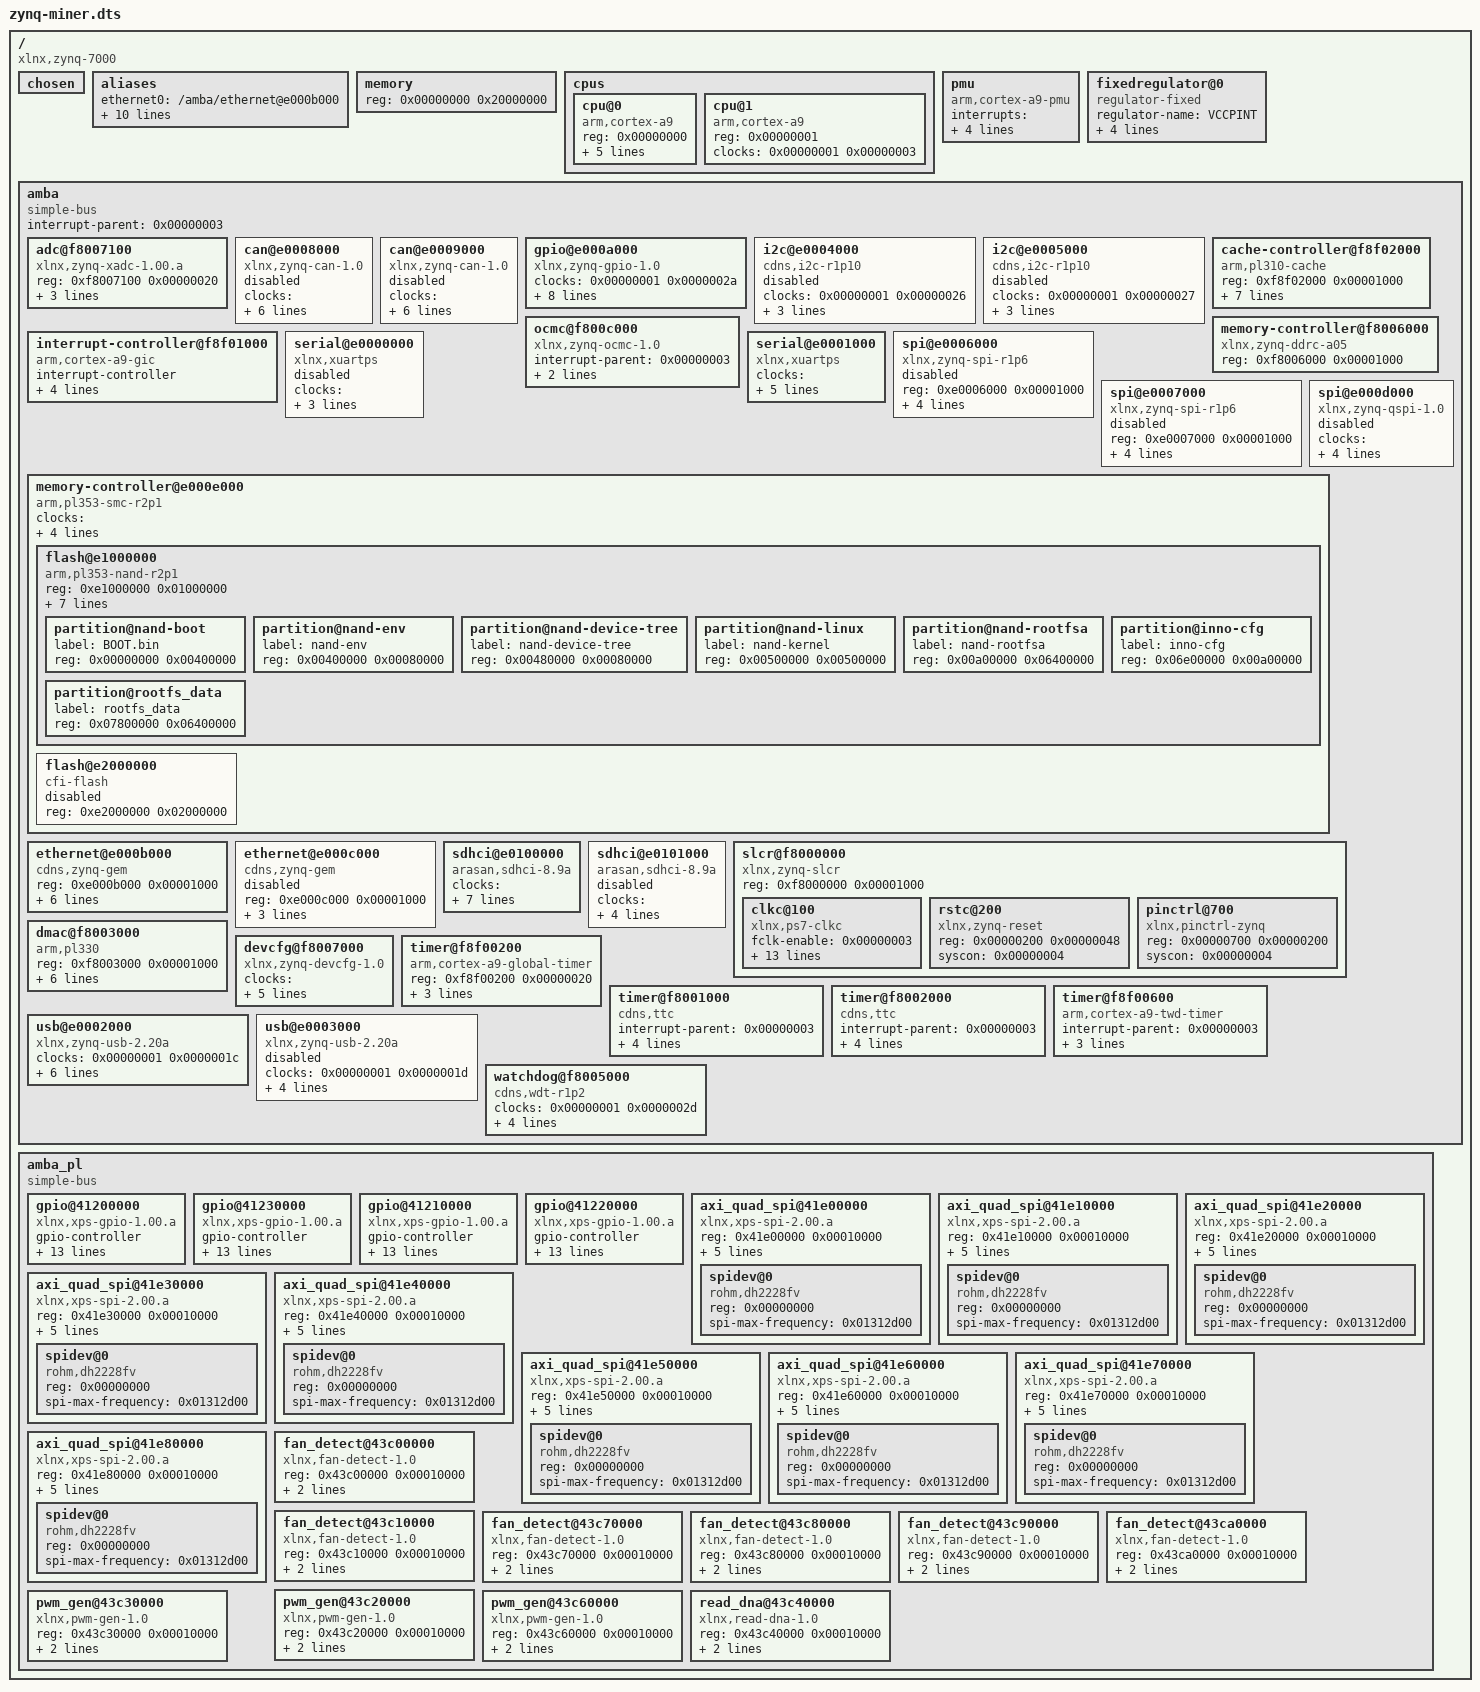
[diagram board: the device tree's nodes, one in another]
/dts-v1/;
// magic:		0xd00dfeed
// totalsize:		0x3c16 (15382)
// off_dt_struct:	0x38
// off_dt_strings:	0x36f0
// off_mem_rsvmap:	0x28
// version:		17
// last_comp_version:	16
// boot_cpuid_phys:	0x0
// size_dt_strings:	0x526
// size_dt_struct:	0x36b8

/ {
    #address-cells = <0x00000001>;
    #size-cells = <0x00000001>;
    compatible = "xlnx,zynq-7000";
    chosen {
    };
    aliases {
        ethernet0 = "/amba/ethernet@e000b000";
        serial0 = "/amba/serial@e0001000";
        spi0 = "/amba_pl/axi_quad_spi@41e00000";
        spi1 = "/amba_pl/axi_quad_spi@41e10000";
        spi2 = "/amba_pl/axi_quad_spi@41e20000";
        spi3 = "/amba_pl/axi_quad_spi@41e30000";
        spi4 = "/amba_pl/axi_quad_spi@41e40000";
        spi5 = "/amba_pl/axi_quad_spi@41e50000";
        spi6 = "/amba_pl/axi_quad_spi@41e60000";
        spi7 = "/amba_pl/axi_quad_spi@41e70000";
        spi8 = "/amba_pl/axi_quad_spi@41e80000";
    };
    memory {
        device_type = "memory";
        reg = <0x00000000 0x20000000>;
    };
    cpus {
        #address-cells = <0x00000001>;
        #size-cells = <0x00000000>;
        cpu@0 {
            compatible = "arm,cortex-a9";
            device_type = "cpu";
            reg = <0x00000000>;
            clocks = <0x00000001 0x00000003>;
            clock-latency = <0x000003e8>;
            cpu0-supply = <0x00000002>;
            operating-points = <0x000a2c2a 0x000f4240 0x00051615 0x000f4240>;
        };
        cpu@1 {
            compatible = "arm,cortex-a9";
            device_type = "cpu";
            reg = <0x00000001>;
            clocks = <0x00000001 0x00000003>;
        };
    };
    pmu {
        compatible = "arm,cortex-a9-pmu";
        interrupts = <0x00000000 0x00000005 0x00000004 0x00000000 0x00000006 0x00000004>;
        interrupt-parent = <0x00000003>;
        reg = <0xf8891000 0x00001000 0xf8893000 0x00001000>;
    };
    fixedregulator@0 {
        compatible = "regulator-fixed";
        regulator-name = "VCCPINT";
        regulator-min-microvolt = <0x000f4240>;
        regulator-max-microvolt = <0x000f4240>;
        regulator-boot-on;
        regulator-always-on;
        linux,phandle = <0x00000002>;
        phandle = <0x00000002>;
    };
    amba {
        compatible = "simple-bus";
        #address-cells = <0x00000001>;
        #size-cells = <0x00000001>;
        interrupt-parent = <0x00000003>;
        ranges;
        adc@f8007100 {
            compatible = "xlnx,zynq-xadc-1.00.a";
            reg = <0xf8007100 0x00000020>;
            interrupts = <0x00000000 0x00000007 0x00000004>;
            interrupt-parent = <0x00000003>;
            clocks = <0x00000001 0x0000000c>;
        };
        can@e0008000 {
            compatible = "xlnx,zynq-can-1.0";
            status = "disabled";
            clocks = <0x00000001 0x00000013 0x00000001 0x00000024>;
            clock-names = "can_clk", "pclk";
            reg = <0xe0008000 0x00001000>;
            interrupts = <0x00000000 0x0000001c 0x00000004>;
            interrupt-parent = <0x00000003>;
            tx-fifo-depth = <0x00000040>;
            rx-fifo-depth = <0x00000040>;
        };
        can@e0009000 {
            compatible = "xlnx,zynq-can-1.0";
            status = "disabled";
            clocks = <0x00000001 0x00000014 0x00000001 0x00000025>;
            clock-names = "can_clk", "pclk";
            reg = <0xe0009000 0x00001000>;
            interrupts = <0x00000000 0x00000033 0x00000004>;
            interrupt-parent = <0x00000003>;
            tx-fifo-depth = <0x00000040>;
            rx-fifo-depth = <0x00000040>;
        };
        gpio@e000a000 {
            compatible = "xlnx,zynq-gpio-1.0";
            #gpio-cells = <0x00000002>;
            #interrupt-cells = <0x00000002>;
            clocks = <0x00000001 0x0000002a>;
            gpio-controller;
            interrupt-controller;
            interrupt-parent = <0x00000003>;
            interrupts = <0x00000000 0x00000014 0x00000004>;
            reg = <0xe000a000 0x00001000>;
            emio-gpio-width = <0x00000040>;
            gpio-mask-high = <0x00000000>;
            gpio-mask-low = <0x00005600>;
            linux,phandle = <0x00000005>;
            phandle = <0x00000005>;
        };
        i2c@e0004000 {
            compatible = "cdns,i2c-r1p10";
            status = "disabled";
            clocks = <0x00000001 0x00000026>;
            interrupt-parent = <0x00000003>;
            interrupts = <0x00000000 0x00000019 0x00000004>;
            reg = <0xe0004000 0x00001000>;
            #address-cells = <0x00000001>;
            #size-cells = <0x00000000>;
        };
        i2c@e0005000 {
            compatible = "cdns,i2c-r1p10";
            status = "disabled";
            clocks = <0x00000001 0x00000027>;
            interrupt-parent = <0x00000003>;
            interrupts = <0x00000000 0x00000030 0x00000004>;
            reg = <0xe0005000 0x00001000>;
            #address-cells = <0x00000001>;
            #size-cells = <0x00000000>;
        };
        interrupt-controller@f8f01000 {
            compatible = "arm,cortex-a9-gic";
            #interrupt-cells = <0x00000003>;
            interrupt-controller;
            reg = <0xf8f01000 0x00001000 0xf8f00100 0x00000100>;
            num_cpus = <0x00000002>;
            num_interrupts = <0x00000060>;
            linux,phandle = <0x00000003>;
            phandle = <0x00000003>;
        };
        cache-controller@f8f02000 {
            compatible = "arm,pl310-cache";
            reg = <0xf8f02000 0x00001000>;
            interrupts = <0x00000000 0x00000002 0x00000004>;
            arm,data-latency = <0x00000003 0x00000002 0x00000002>;
            arm,tag-latency = <0x00000002 0x00000002 0x00000002>;
            cache-unified;
            cache-level = <0x00000002>;
        };
        memory-controller@f8006000 {
            compatible = "xlnx,zynq-ddrc-a05";
            reg = <0xf8006000 0x00001000>;
        };
        ocmc@f800c000 {
            compatible = "xlnx,zynq-ocmc-1.0";
            interrupt-parent = <0x00000003>;
            interrupts = <0x00000000 0x00000003 0x00000004>;
            reg = <0xf800c000 0x00001000>;
        };
        serial@e0000000 {
            compatible = "xlnx,xuartps", "cdns,uart-r1p8";
            status = "disabled";
            clocks = <0x00000001 0x00000017 0x00000001 0x00000028>;
            clock-names = "uart_clk", "pclk";
            reg = <0xe0000000 0x00001000>;
            interrupts = <0x00000000 0x0000001b 0x00000004>;
        };
        serial@e0001000 {
            compatible = "xlnx,xuartps", "cdns,uart-r1p8";
            status = "okay";
            clocks = <0x00000001 0x00000018 0x00000001 0x00000029>;
            clock-names = "uart_clk", "pclk";
            reg = <0xe0001000 0x00001000>;
            interrupts = <0x00000000 0x00000032 0x00000004>;
            current-speed = <0x0001c200>;
            device_type = "serial";
            port-number = <0x00000000>;
        };
        spi@e0006000 {
            compatible = "xlnx,zynq-spi-r1p6";
            reg = <0xe0006000 0x00001000>;
            status = "disabled";
            interrupt-parent = <0x00000003>;
            interrupts = <0x00000000 0x0000001a 0x00000004>;
            clocks = <0x00000001 0x00000019 0x00000001 0x00000022>;
            clock-names = "ref_clk", "pclk";
            #address-cells = <0x00000001>;
            #size-cells = <0x00000000>;
        };
        spi@e0007000 {
            compatible = "xlnx,zynq-spi-r1p6";
            reg = <0xe0007000 0x00001000>;
            status = "disabled";
            interrupt-parent = <0x00000003>;
            interrupts = <0x00000000 0x00000031 0x00000004>;
            clocks = <0x00000001 0x0000001a 0x00000001 0x00000023>;
            clock-names = "ref_clk", "pclk";
            #address-cells = <0x00000001>;
            #size-cells = <0x00000000>;
        };
        spi@e000d000 {
            clock-names = "ref_clk", "pclk";
            clocks = <0x00000001 0x0000000a 0x00000001 0x0000002b>;
            compatible = "xlnx,zynq-qspi-1.0";
            status = "disabled";
            interrupt-parent = <0x00000003>;
            interrupts = <0x00000000 0x00000013 0x00000004>;
            reg = <0xe000d000 0x00001000>;
            #address-cells = <0x00000001>;
            #size-cells = <0x00000000>;
        };
        memory-controller@e000e000 {
            #address-cells = <0x00000001>;
            #size-cells = <0x00000001>;
            status = "okay";
            clock-names = "memclk", "aclk";
            clocks = <0x00000001 0x0000000b 0x00000001 0x0000002c>;
            compatible = "arm,pl353-smc-r2p1";
            interrupt-parent = <0x00000003>;
            interrupts = <0x00000000 0x00000012 0x00000004>;
            ranges;
            reg = <0xe000e000 0x00001000>;
            flash@e1000000 {
                status = "okay";
                compatible = "arm,pl353-nand-r2p1";
                reg = <0xe1000000 0x01000000>;
                #address-cells = <0x00000001>;
                #size-cells = <0x00000001>;
                arm,nand-cycle-t0 = <0x00000003>;
                arm,nand-cycle-t1 = <0x00000003>;
                arm,nand-cycle-t2 = <0x00000001>;
                arm,nand-cycle-t3 = <0x00000001>;
                arm,nand-cycle-t4 = <0x00000002>;
                arm,nand-cycle-t5 = <0x00000001>;
                arm,nand-cycle-t6 = <0x00000002>;
                partition@nand-boot {
                    label = "BOOT.bin";
                    reg = <0x00000000 0x00400000>;
                };
                partition@nand-env {
                    label = "nand-env";
                    reg = <0x00400000 0x00080000>;
                };
                partition@nand-device-tree {
                    label = "nand-device-tree";
                    reg = <0x00480000 0x00080000>;
                };
                partition@nand-linux {
                    label = "nand-kernel";
                    reg = <0x00500000 0x00500000>;
                };
                partition@nand-rootfsa {
                    label = "nand-rootfsa";
                    reg = <0x00a00000 0x06400000>;
                };
                partition@inno-cfg {
                    label = "inno-cfg";
                    reg = <0x06e00000 0x00a00000>;
                };
                partition@rootfs_data {
                    label = "rootfs_data";
                    reg = <0x07800000 0x06400000>;
                };
            };
            flash@e2000000 {
                status = "disabled";
                compatible = "cfi-flash";
                reg = <0xe2000000 0x02000000>;
                #address-cells = <0x00000001>;
                #size-cells = <0x00000001>;
            };
        };
        ethernet@e000b000 {
            compatible = "cdns,zynq-gem", "cdns,gem";
            reg = <0xe000b000 0x00001000>;
            status = "okay";
            interrupts = <0x00000000 0x00000016 0x00000004>;
            clocks = <0x00000001 0x0000001e 0x00000001 0x0000001e 0x00000001 0x0000000d>;
            clock-names = "pclk", "hclk", "tx_clk";
            #address-cells = <0x00000001>;
            #size-cells = <0x00000000>;
            local-mac-address = [00 0a 35 00 00 00];
            phy-mode = "rgmii-id";
            xlnx,ptp-enet-clock = <0x069f6bcb>;
        };
        ethernet@e000c000 {
            compatible = "cdns,zynq-gem", "cdns,gem";
            reg = <0xe000c000 0x00001000>;
            status = "disabled";
            interrupts = <0x00000000 0x0000002d 0x00000004>;
            clocks = <0x00000001 0x0000001f 0x00000001 0x0000001f 0x00000001 0x0000000e>;
            clock-names = "pclk", "hclk", "tx_clk";
            #address-cells = <0x00000001>;
            #size-cells = <0x00000000>;
        };
        sdhci@e0100000 {
            compatible = "arasan,sdhci-8.9a";
            status = "okay";
            clock-names = "clk_xin", "clk_ahb";
            clocks = <0x00000001 0x00000015 0x00000001 0x00000020>;
            interrupt-parent = <0x00000003>;
            interrupts = <0x00000000 0x00000018 0x00000004>;
            reg = <0xe0100000 0x00001000>;
            xlnx,has-cd = <0x00000001>;
            xlnx,has-power = <0x00000000>;
            xlnx,has-wp = <0x00000000>;
        };
        sdhci@e0101000 {
            compatible = "arasan,sdhci-8.9a";
            status = "disabled";
            clock-names = "clk_xin", "clk_ahb";
            clocks = <0x00000001 0x00000016 0x00000001 0x00000021>;
            interrupt-parent = <0x00000003>;
            interrupts = <0x00000000 0x0000002f 0x00000004>;
            reg = <0xe0101000 0x00001000>;
        };
        slcr@f8000000 {
            #address-cells = <0x00000001>;
            #size-cells = <0x00000001>;
            compatible = "xlnx,zynq-slcr", "syscon", "simple-bus";
            reg = <0xf8000000 0x00001000>;
            ranges;
            linux,phandle = <0x00000004>;
            phandle = <0x00000004>;
            clkc@100 {
                #clock-cells = <0x00000001>;
                compatible = "xlnx,ps7-clkc";
                fclk-enable = <0x00000003>;
                clock-output-names = "armpll", "ddrpll", "iopll", "cpu_6or4x", "cpu_3or2x", "cpu_2x", "cpu_1x", "ddr2x", "ddr3x", "dci", "lqspi", "smc", "pcap", "gem0", "gem1", "fclk0", "fclk1", "fclk2", "fclk3", "can0", "can1", "sdio0", "sdio1", "uart0", "uart1", "spi0", "spi1", "dma", "usb0_aper", "usb1_aper", "gem0_aper", "gem1_aper", "sdio0_aper", "sdio1_aper", "spi0_aper", "spi1_aper", "can0_aper", "can1_aper", "i2c0_aper", "i2c1_aper", "uart0_aper", "uart1_aper", "gpio_aper", "lqspi_aper", "smc_aper", "swdt", "dbg_trc", "dbg_apb";
                reg = <0x00000100 0x00000100>;
                ps-clk-frequency = <0x01fca055>;
                linux,phandle = <0x00000001>;
                phandle = <0x00000001>;
            };
            rstc@200 {
                compatible = "xlnx,zynq-reset";
                reg = <0x00000200 0x00000048>;
                #reset-cells = <0x00000001>;
                syscon = <0x00000004>;
            };
            pinctrl@700 {
                compatible = "xlnx,pinctrl-zynq";
                reg = <0x00000700 0x00000200>;
                syscon = <0x00000004>;
            };
        };
        dmac@f8003000 {
            compatible = "arm,pl330", "arm,primecell";
            reg = <0xf8003000 0x00001000>;
            interrupt-parent = <0x00000003>;
            interrupt-names = "abort", "dma0", "dma1", "dma2", "dma3", "dma4", "dma5", "dma6", "dma7";
            interrupts = <0x00000000 0x0000000d 0x00000004 0x00000000 0x0000000e 0x00000004 0x00000000 0x0000000f 0x00000004 0x00000000 0x00000010 0x00000004 0x00000000 0x00000011 0x00000004 0x00000000 0x00000028 0x00000004 0x00000000 0x00000029 0x00000004 0x00000000 0x0000002a 0x00000004 0x00000000 0x0000002b 0x00000004>;
            #dma-cells = <0x00000001>;
            #dma-channels = <0x00000008>;
            #dma-requests = <0x00000004>;
            clocks = <0x00000001 0x0000001b>;
            clock-names = "apb_pclk";
        };
        devcfg@f8007000 {
            clock-names = "ref_clk", "fclk0", "fclk1", "fclk2", "fclk3";
            clocks = <0x00000001 0x0000000c 0x00000001 0x0000000f 0x00000001 0x00000010 0x00000001 0x00000011 0x00000001 0x00000012>;
            compatible = "xlnx,zynq-devcfg-1.0";
            interrupt-parent = <0x00000003>;
            interrupts = <0x00000000 0x00000008 0x00000004>;
            reg = <0xf8007000 0x00000100>;
            syscon = <0x00000004>;
        };
        timer@f8f00200 {
            compatible = "arm,cortex-a9-global-timer";
            reg = <0xf8f00200 0x00000020>;
            interrupts = <0x00000001 0x0000000b 0x00000301>;
            interrupt-parent = <0x00000003>;
            clocks = <0x00000001 0x00000004>;
        };
        timer@f8001000 {
            interrupt-parent = <0x00000003>;
            interrupts = <0x00000000 0x0000000a 0x00000004 0x00000000 0x0000000b 0x00000004 0x00000000 0x0000000c 0x00000004>;
            compatible = "cdns,ttc";
            clocks = <0x00000001 0x00000006>;
            reg = <0xf8001000 0x00001000>;
        };
        timer@f8002000 {
            interrupt-parent = <0x00000003>;
            interrupts = <0x00000000 0x00000025 0x00000004 0x00000000 0x00000026 0x00000004 0x00000000 0x00000027 0x00000004>;
            compatible = "cdns,ttc";
            clocks = <0x00000001 0x00000006>;
            reg = <0xf8002000 0x00001000>;
        };
        timer@f8f00600 {
            interrupt-parent = <0x00000003>;
            interrupts = <0x00000001 0x0000000d 0x00000301>;
            compatible = "arm,cortex-a9-twd-timer";
            reg = <0xf8f00600 0x00000020>;
            clocks = <0x00000001 0x00000004>;
        };
        usb@e0002000 {
            compatible = "xlnx,zynq-usb-2.20a", "chipidea,usb2";
            status = "okay";
            clocks = <0x00000001 0x0000001c>;
            interrupt-parent = <0x00000003>;
            interrupts = <0x00000000 0x00000015 0x00000004>;
            reg = <0xe0002000 0x00001000>;
            phy_type = "ulpi";
            dr_mode = "host";
            usb-reset = <0x00000005 0x0000002e 0x00000000>;
        };
        usb@e0003000 {
            compatible = "xlnx,zynq-usb-2.20a", "chipidea,usb2";
            status = "disabled";
            clocks = <0x00000001 0x0000001d>;
            interrupt-parent = <0x00000003>;
            interrupts = <0x00000000 0x0000002c 0x00000004>;
            reg = <0xe0003000 0x00001000>;
            phy_type = "ulpi";
        };
        watchdog@f8005000 {
            clocks = <0x00000001 0x0000002d>;
            compatible = "cdns,wdt-r1p2";
            interrupt-parent = <0x00000003>;
            interrupts = <0x00000000 0x00000009 0x00000001>;
            reg = <0xf8005000 0x00001000>;
            timeout-sec = <0x0000000a>;
        };
    };
    amba_pl {
        #address-cells = <0x00000001>;
        #size-cells = <0x00000001>;
        compatible = "simple-bus";
        ranges;
        gpio@41200000 {
            #gpio-cells = <0x00000002>;
            compatible = "xlnx,xps-gpio-1.00.a";
            gpio-controller;
            reg = <0x41200000 0x00010000>;
            xlnx,all-inputs = <0x00000001>;
            xlnx,all-inputs-2 = <0x00000000>;
            xlnx,all-outputs = <0x00000000>;
            xlnx,all-outputs-2 = <0x00000000>;
            xlnx,dout-default = <0x00000000>;
            xlnx,dout-default-2 = <0x00000000>;
            xlnx,gpio-width = <0x0000000a>;
            xlnx,gpio2-width = <0x00000020>;
            xlnx,interrupt-present = <0x00000000>;
            xlnx,is-dual = <0x00000000>;
            xlnx,tri-default = <0xffffffff>;
            xlnx,tri-default-2 = <0xffffffff>;
        };
        gpio@41230000 {
            #gpio-cells = <0x00000002>;
            compatible = "xlnx,xps-gpio-1.00.a";
            gpio-controller;
            reg = <0x41230000 0x00010000>;
            xlnx,all-inputs = <0x00000001>;
            xlnx,all-inputs-2 = <0x00000000>;
            xlnx,all-outputs = <0x00000000>;
            xlnx,all-outputs-2 = <0x00000000>;
            xlnx,dout-default = <0x00000000>;
            xlnx,dout-default-2 = <0x00000000>;
            xlnx,gpio-width = <0x00000001>;
            xlnx,gpio2-width = <0x00000020>;
            xlnx,interrupt-present = <0x00000000>;
            xlnx,is-dual = <0x00000000>;
            xlnx,tri-default = <0xffffffff>;
            xlnx,tri-default-2 = <0xffffffff>;
        };
        gpio@41210000 {
            #gpio-cells = <0x00000002>;
            compatible = "xlnx,xps-gpio-1.00.a";
            gpio-controller;
            reg = <0x41210000 0x00010000>;
            xlnx,all-inputs = <0x00000000>;
            xlnx,all-inputs-2 = <0x00000000>;
            xlnx,all-outputs = <0x00000001>;
            xlnx,all-outputs-2 = <0x00000000>;
            xlnx,dout-default = <0x00000000>;
            xlnx,dout-default-2 = <0x00000000>;
            xlnx,gpio-width = <0x0000001c>;
            xlnx,gpio2-width = <0x00000020>;
            xlnx,interrupt-present = <0x00000000>;
            xlnx,is-dual = <0x00000000>;
            xlnx,tri-default = <0xffffffff>;
            xlnx,tri-default-2 = <0xffffffff>;
        };
        gpio@41220000 {
            #gpio-cells = <0x00000002>;
            compatible = "xlnx,xps-gpio-1.00.a";
            gpio-controller;
            reg = <0x41220000 0x00010000>;
            xlnx,all-inputs = <0x00000000>;
            xlnx,all-inputs-2 = <0x00000000>;
            xlnx,all-outputs = <0x00000001>;
            xlnx,all-outputs-2 = <0x00000000>;
            xlnx,dout-default = <0x00000000>;
            xlnx,dout-default-2 = <0x00000000>;
            xlnx,gpio-width = <0x0000000d>;
            xlnx,gpio2-width = <0x00000020>;
            xlnx,interrupt-present = <0x00000000>;
            xlnx,is-dual = <0x00000000>;
            xlnx,tri-default = <0xffffffff>;
            xlnx,tri-default-2 = <0xffffffff>;
        };
        axi_quad_spi@41e00000 {
            compatible = "xlnx,xps-spi-2.00.a";
            reg = <0x41e00000 0x00010000>;
            xlnx,num-ss-bits = <0x00000001>;
            bits-per-word = <0x00000008>;
            fifo-size = <0x00000100>;
            xlnx,spi-mode = <0x00000001>;
            num-cs = <0x00000001>;
            spidev@0 {
                compatible = "rohm,dh2228fv";
                #address-cells = <0x00000001>;
                #size-cells = <0x00000000>;
                reg = <0x00000000>;
                spi-max-frequency = <0x01312d00>;
            };
        };
        axi_quad_spi@41e10000 {
            compatible = "xlnx,xps-spi-2.00.a";
            reg = <0x41e10000 0x00010000>;
            xlnx,num-ss-bits = <0x00000001>;
            bits-per-word = <0x00000008>;
            fifo-size = <0x00000100>;
            xlnx,spi-mode = <0x00000001>;
            num-cs = <0x00000001>;
            spidev@0 {
                compatible = "rohm,dh2228fv";
                #address-cells = <0x00000001>;
                #size-cells = <0x00000000>;
                reg = <0x00000000>;
                spi-max-frequency = <0x01312d00>;
            };
        };
        axi_quad_spi@41e20000 {
            compatible = "xlnx,xps-spi-2.00.a";
            reg = <0x41e20000 0x00010000>;
            xlnx,num-ss-bits = <0x00000001>;
            bits-per-word = <0x00000008>;
            fifo-size = <0x00000100>;
            xlnx,spi-mode = <0x00000001>;
            num-cs = <0x00000001>;
            spidev@0 {
                compatible = "rohm,dh2228fv";
                #address-cells = <0x00000001>;
                #size-cells = <0x00000000>;
                reg = <0x00000000>;
                spi-max-frequency = <0x01312d00>;
            };
        };
        axi_quad_spi@41e30000 {
            compatible = "xlnx,xps-spi-2.00.a";
            reg = <0x41e30000 0x00010000>;
            xlnx,num-ss-bits = <0x00000001>;
            bits-per-word = <0x00000008>;
            fifo-size = <0x00000100>;
            xlnx,spi-mode = <0x00000001>;
            num-cs = <0x00000001>;
            spidev@0 {
                compatible = "rohm,dh2228fv";
                #address-cells = <0x00000001>;
                #size-cells = <0x00000000>;
                reg = <0x00000000>;
                spi-max-frequency = <0x01312d00>;
            };
        };
        axi_quad_spi@41e40000 {
            compatible = "xlnx,xps-spi-2.00.a";
            reg = <0x41e40000 0x00010000>;
            xlnx,num-ss-bits = <0x00000001>;
            bits-per-word = <0x00000008>;
            fifo-size = <0x00000100>;
            xlnx,spi-mode = <0x00000001>;
            num-cs = <0x00000001>;
            spidev@0 {
                compatible = "rohm,dh2228fv";
                #address-cells = <0x00000001>;
                #size-cells = <0x00000000>;
                reg = <0x00000000>;
                spi-max-frequency = <0x01312d00>;
            };
        };
        axi_quad_spi@41e50000 {
            compatible = "xlnx,xps-spi-2.00.a";
            reg = <0x41e50000 0x00010000>;
            xlnx,num-ss-bits = <0x00000001>;
            bits-per-word = <0x00000008>;
            fifo-size = <0x00000100>;
            xlnx,spi-mode = <0x00000001>;
            num-cs = <0x00000001>;
            spidev@0 {
                compatible = "rohm,dh2228fv";
                #address-cells = <0x00000001>;
                #size-cells = <0x00000000>;
                reg = <0x00000000>;
                spi-max-frequency = <0x01312d00>;
            };
        };
        axi_quad_spi@41e60000 {
            compatible = "xlnx,xps-spi-2.00.a";
            reg = <0x41e60000 0x00010000>;
            xlnx,num-ss-bits = <0x00000001>;
            bits-per-word = <0x00000008>;
            fifo-size = <0x00000100>;
            xlnx,spi-mode = <0x00000001>;
            num-cs = <0x00000001>;
            spidev@0 {
                compatible = "rohm,dh2228fv";
                #address-cells = <0x00000001>;
                #size-cells = <0x00000000>;
                reg = <0x00000000>;
                spi-max-frequency = <0x01312d00>;
            };
        };
        axi_quad_spi@41e70000 {
            compatible = "xlnx,xps-spi-2.00.a";
            reg = <0x41e70000 0x00010000>;
            xlnx,num-ss-bits = <0x00000001>;
            bits-per-word = <0x00000008>;
            fifo-size = <0x00000100>;
            xlnx,spi-mode = <0x00000001>;
            num-cs = <0x00000001>;
            spidev@0 {
                compatible = "rohm,dh2228fv";
                #address-cells = <0x00000001>;
                #size-cells = <0x00000000>;
                reg = <0x00000000>;
                spi-max-frequency = <0x01312d00>;
            };
        };
        axi_quad_spi@41e80000 {
            compatible = "xlnx,xps-spi-2.00.a";
            reg = <0x41e80000 0x00010000>;
            xlnx,num-ss-bits = <0x00000001>;
            bits-per-word = <0x00000008>;
            fifo-size = <0x00000100>;
            xlnx,spi-mode = <0x00000001>;
            num-cs = <0x00000001>;
            spidev@0 {
                compatible = "rohm,dh2228fv";
                #address-cells = <0x00000001>;
                #size-cells = <0x00000000>;
                reg = <0x00000000>;
                spi-max-frequency = <0x01312d00>;
            };
        };
        fan_detect@43c00000 {
            compatible = "xlnx,fan-detect-1.0";
            reg = <0x43c00000 0x00010000>;
            xlnx,s00-axi-addr-width = <0x00000004>;
            xlnx,s00-axi-data-width = <0x00000020>;
        };
        fan_detect@43c10000 {
            compatible = "xlnx,fan-detect-1.0";
            reg = <0x43c10000 0x00010000>;
            xlnx,s00-axi-addr-width = <0x00000004>;
            xlnx,s00-axi-data-width = <0x00000020>;
        };
        fan_detect@43c70000 {
            compatible = "xlnx,fan-detect-1.0";
            reg = <0x43c70000 0x00010000>;
            xlnx,s00-axi-addr-width = <0x00000004>;
            xlnx,s00-axi-data-width = <0x00000020>;
        };
        fan_detect@43c80000 {
            compatible = "xlnx,fan-detect-1.0";
            reg = <0x43c80000 0x00010000>;
            xlnx,s00-axi-addr-width = <0x00000004>;
            xlnx,s00-axi-data-width = <0x00000020>;
        };
        fan_detect@43c90000 {
            compatible = "xlnx,fan-detect-1.0";
            reg = <0x43c90000 0x00010000>;
            xlnx,s00-axi-addr-width = <0x00000004>;
            xlnx,s00-axi-data-width = <0x00000020>;
        };
        fan_detect@43ca0000 {
            compatible = "xlnx,fan-detect-1.0";
            reg = <0x43ca0000 0x00010000>;
            xlnx,s00-axi-addr-width = <0x00000004>;
            xlnx,s00-axi-data-width = <0x00000020>;
        };
        pwm_gen@43c20000 {
            compatible = "xlnx,pwm-gen-1.0";
            reg = <0x43c20000 0x00010000>;
            xlnx,s00-axi-addr-width = <0x00000004>;
            xlnx,s00-axi-data-width = <0x00000020>;
        };
        pwm_gen@43c30000 {
            compatible = "xlnx,pwm-gen-1.0";
            reg = <0x43c30000 0x00010000>;
            xlnx,s00-axi-addr-width = <0x00000004>;
            xlnx,s00-axi-data-width = <0x00000020>;
        };
        pwm_gen@43c60000 {
            compatible = "xlnx,pwm-gen-1.0";
            reg = <0x43c60000 0x00010000>;
            xlnx,s00-axi-addr-width = <0x00000004>;
            xlnx,s00-axi-data-width = <0x00000020>;
        };
        read_dna@43c40000 {
            compatible = "xlnx,read-dna-1.0";
            reg = <0x43c40000 0x00010000>;
            xlnx,s00-axi-addr-width = <0x00000004>;
            xlnx,s00-axi-data-width = <0x00000020>;
        };
    };
};
